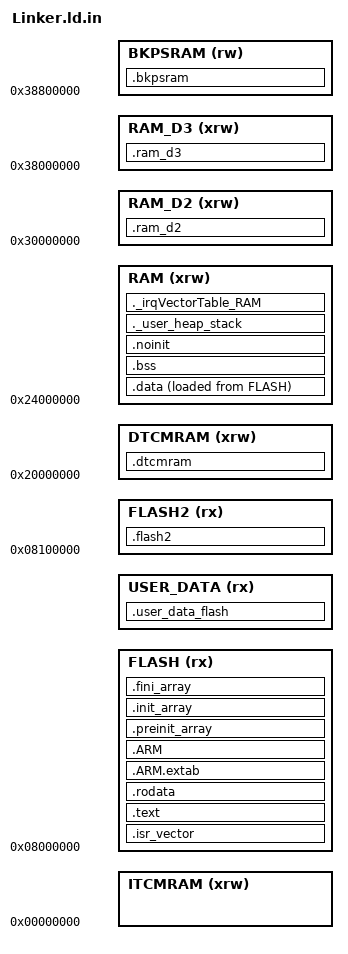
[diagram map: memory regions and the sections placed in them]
/*******************************************************************************
**
** @file        : Linker.ld.in
**
** @author      : Eifell
**
** @brief       : Linker script for STM32H7xx Device from STM32H7 series
**
**                Set heap size, stack size and stack location according
**                to application requirements.
**
**                Set memory bank area and size if external memory is used
**
**  Target      : STMicroelectronics STM32H7 family
**
**  Distribution: The file is distributed as is, without any warranty
**                of any kind.
**
********************************************************************************
** @attention
**
** This software is licensed under terms that can be found in the LICENSE file
** in the root directory of this software component.
** If no LICENSE file comes with this software, it is provided AS-IS.
**
********************************************************************************
*/

/* Entry Point */
ENTRY(StartUp_Handler)

/* Memories definition
 * RAM is the AXI SRAM (D1 / CD domain) - accessible by the CPU and by all DMA
 * controllers. DTCMRAM / ITCMRAM are accessible by the CPU (and MDMA) only.
 * RAM_D2 is the AHB SRAM of D2 / CD domain, RAM_D3 the SRAM of D3 / SRD domain
 * (the only RAM accessible by BDMA). FLASH is bank 1, FLASH2 is bank 2 when the
 * banks are not contiguous (1M dual-bank devices), dual-core devices use bank 1
 * only. */
MEMORY
{
  RAM      (xrw) : ORIGIN = 0x24000000,                    LENGTH = @RAM_SIZE@
  DTCMRAM  (xrw) : ORIGIN = 0x20000000,                    LENGTH = @DTCMRAM_SIZE@
  ITCMRAM  (xrw) : ORIGIN = 0x00000000,                    LENGTH = @ITCMRAM_SIZE@
  RAM_D2   (xrw) : ORIGIN = 0x30000000,                    LENGTH = @RAM_D2_SIZE@
  RAM_D3   (xrw) : ORIGIN = 0x38000000,                    LENGTH = @RAM_D3_SIZE@
  BKPSRAM   (rw) : ORIGIN = 0x38800000,                    LENGTH = @BKPSRAM_SIZE@
  FLASH     (rx) : ORIGIN = 0x08000000,                    LENGTH = @FLASH_SIZE@ - @USER_DATA_SIZE@
  USER_DATA (rx) : ORIGIN = ORIGIN(FLASH) + LENGTH(FLASH), LENGTH = @USER_DATA_SIZE@
  FLASH2    (rx) : ORIGIN = 0x08100000,                    LENGTH = @FLASH2_SIZE@
}

_ram_start  = ORIGIN(RAM);
_ram_length = LENGTH(RAM);
_ram_end    = ORIGIN(RAM) + LENGTH(RAM);

_dtcmram_start  = ORIGIN(DTCMRAM);
_dtcmram_length = LENGTH(DTCMRAM);
_dtcmram_end    = ORIGIN(DTCMRAM) + LENGTH(DTCMRAM);

_itcmram_start  = ORIGIN(ITCMRAM);
_itcmram_length = LENGTH(ITCMRAM);
_itcmram_end    = ORIGIN(ITCMRAM) + LENGTH(ITCMRAM);

_ram_d2_start  = ORIGIN(RAM_D2);
_ram_d2_length = LENGTH(RAM_D2);
_ram_d2_end    = ORIGIN(RAM_D2) + LENGTH(RAM_D2);

_ram_d3_start  = ORIGIN(RAM_D3);
_ram_d3_length = LENGTH(RAM_D3);
_ram_d3_end    = ORIGIN(RAM_D3) + LENGTH(RAM_D3);

_bkpsram_start  = ORIGIN(BKPSRAM);
_bkpsram_length = LENGTH(BKPSRAM);
_bkpsram_end    = ORIGIN(BKPSRAM) + LENGTH(BKPSRAM);

_flash_start  = ORIGIN(FLASH);
_flash_length = LENGTH(FLASH);
_flash_end    = ORIGIN(FLASH) + LENGTH(FLASH);

_flash2_start  = ORIGIN(FLASH2);
_flash2_length = LENGTH(FLASH2);
_flash2_end    = ORIGIN(FLASH2) + LENGTH(FLASH2);


/* Highest address of the user mode stack */
_estack = ORIGIN(RAM) + LENGTH(RAM); /* end of "RAM" Ram type memory */

_Min_Heap_Size = 0x200;  /* required amount of heap */
_Min_Stack_Size = 0x400; /* required amount of stack */


/* Sections */
SECTIONS
{
  /* The startup code into "FLASH" Rom type memory */
  .isr_vector (READONLY) :
  {
    . = ALIGN(4);
    KEEP(*(.isr_vector)) /* Startup code */
    . = ALIGN(4);
  } >FLASH


  /* The program code and other data into "FLASH" Rom type memory */
  .text :
  {
    . = ALIGN(4);
    *(.text)           /* .text sections (code) */
    *(.text*)          /* .text* sections (code) */
    *(.glue_7)         /* glue arm to thumb code */
    *(.glue_7t)        /* glue thumb to arm code */
    *(.eh_frame)

    KEEP (*(.init))
    KEEP (*(.fini))

    . = ALIGN(4);
    _etext = .;        /* define a global symbols at end of code */
  } >FLASH


  /* Constant data into "FLASH" Rom type memory */
  .rodata :
  {
    . = ALIGN(4);
    *(.rodata)         /* .rodata sections (constants, strings, etc.) */
    *(.rodata*)        /* .rodata* sections (constants, strings, etc.) */
    . = ALIGN(4);
  } >FLASH


  /* Location of user data */
  .user_data_flash ( NOLOAD ):
  {
    . = ALIGN(4);
    _user_data_flash_start = .;
    *(.user_data_flash)
    _user_data_flash_end = .;
    . = ALIGN(4);
  } >USER_DATA


  .ARM.extab :
  {
    . = ALIGN(4);
    *(.ARM.extab* .gnu.linkonce.armextab.*)
    . = ALIGN(4);
  } >FLASH


  .ARM :
  {
    . = ALIGN(4);
    __exidx_start = .;
    *(.ARM.exidx*)
    __exidx_end = .;
    . = ALIGN(4);
  } >FLASH


  .preinit_array (READONLY) :
  {
    . = ALIGN(4);
    PROVIDE_HIDDEN (__preinit_array_start = .);
    KEEP (*(.preinit_array*))
    PROVIDE_HIDDEN (__preinit_array_end = .);
    . = ALIGN(4);
  } >FLASH


  .init_array (READONLY) :
  {
    . = ALIGN(4);
    PROVIDE_HIDDEN (__init_array_start = .);
    KEEP (*(SORT(.init_array.*)))
    KEEP (*(.init_array*))
    PROVIDE_HIDDEN (__init_array_end = .);
    . = ALIGN(4);
  } >FLASH


  .fini_array (READONLY) :
  {
    . = ALIGN(4);
    PROVIDE_HIDDEN (__fini_array_start = .);
    KEEP (*(SORT(.fini_array.*)))
    KEEP (*(.fini_array*))
    PROVIDE_HIDDEN (__fini_array_end = .);
    . = ALIGN(4);
  } >FLASH


  /* Used by the startup to initialize data */
  _sidata = LOADADDR(.data);

  /* Initialized data sections into "RAM" Ram type memory */
  .data :
  {
    . = ALIGN(4);
    _sdata = .;        /* create a global symbol at data start */
    *(.data)           /* .data sections */
    *(.data*)          /* .data* sections */
    *(.RamFunc)        /* .RamFunc sections */
    *(.RamFunc*)       /* .RamFunc* sections */

    . = ALIGN(4);
    _edata = .;        /* define a global symbol at data end */

  } >RAM AT> FLASH


  /* Uninitialized data section into "RAM" Ram type memory */
  . = ALIGN(4);
  .bss :
  {
    /* This is used by the startup in order to initialize the .bss section */
    _sbss = .;         /* define a global symbol at bss start */
    __bss_start__ = _sbss;
    *(.bss)
    *(.bss*)
    *(COMMON)

    . = ALIGN(4);
    _ebss = .;         /* define a global symbol at bss end */
    __bss_end__ = _ebss;
  } >RAM


  /* Data not initialized by StartUp - content is kept over system reset
   * (eg. result mailbox of integration test firmware) */
  .noinit (NOLOAD) :
  {
    . = ALIGN(4);
    *(.noinit)
    *(.noinit*)
    . = ALIGN(4);
  } >RAM


  /* User_heap_stack section, used to check that there is enough "RAM" Ram  type memory left */
  ._user_heap_stack :
  {
    . = ALIGN(8);
    PROVIDE ( end = . );
    PROVIDE ( _end = . );
    . = . + _Min_Heap_Size;
    . = . + _Min_Stack_Size;
    . = ALIGN(8);
  } >RAM


    /* Application interrupt vector table located in RAM. Content is written
     * at runtime by NVIC module (Nvic_Init), nothing is loaded from FLASH. */
  ._irqVectorTable_RAM (NOLOAD) :
  {
      /* VTOR requires alignment to power of two >= (count of exceptions x 4),
       * STM32H7 table has up to 716 bytes (STM32H723/H725/H730/H733/H735) */
      . = ALIGN(1024);
      _irqVectorTable_RAM_Start = .;

      KEEP( *(._irqVectorTable_RAM))
      KEEP( *(._irqVectorTable_RAM*))

      _irqVectorTable_RAM_End = .;
  } >RAM


  /* Data placed into DTCM (128K, 64K on STM32H7R/S) - zero wait state RAM of
   * the CPU, not accessible by DMA1 / DMA2 / BDMA. Content is not initialized
   * by StartUp. */
  .dtcmram (NOLOAD) :
  {
    . = ALIGN(4);
    _sdtcmram = .;
    *(.dtcmram)
    *(.dtcmram*)
    . = ALIGN(4);
    _edtcmram = .;
  } >DTCMRAM


  /* Data placed into the AHB SRAM of D2 / CD domain (DMA1 / DMA2 buffers of
   * D2 peripherals, Ethernet descriptors, ...). Content is not initialized by
   * StartUp. */
  .ram_d2 (NOLOAD) :
  {
    . = ALIGN(4);
    _sram_d2 = .;
    *(.ram_d2)
    *(.ram_d2*)
    . = ALIGN(4);
    _eram_d2 = .;
  } >RAM_D2


  /* Data placed into the SRAM of D3 / SRD domain - the only RAM accessible by
   * BDMA (not available on STM32H7R/S). Content is not initialized by StartUp. */
  .ram_d3 (NOLOAD) :
  {
    . = ALIGN(4);
    _sram_d3 = .;
    *(.ram_d3)
    *(.ram_d3*)
    . = ALIGN(4);
    _eram_d3 = .;
  } >RAM_D3


  /* Data placed into Backup SRAM (4K, battery backed when VBAT is supplied).
   * BKPSRAM clock and backup domain write access have to be enabled before
   * use. Content is not initialized by StartUp. */
  .bkpsram (NOLOAD) :
  {
    . = ALIGN(4);
    _sbkpsram = .;
    *(.bkpsram)
    *(.bkpsram*)
    . = ALIGN(4);
    _ebkpsram = .;
  } >BKPSRAM


  /* Constant data placed into FLASH bank 2 of 1M dual-bank devices (bank 2 is
   * not contiguous with bank 1) */
  .flash2 (READONLY) :
  {
    . = ALIGN(4);
    _sflash2 = .;
    KEEP(*(.flash2))
    KEEP(*(.flash2*))
    . = ALIGN(4);
    _eflash2 = .;
  } >FLASH2


  /* Remove information from the compiler libraries */
  /DISCARD/ :
  {
    libc.a ( * )
    libm.a ( * )
    libgcc.a ( * )
  }

  .ARM.attributes 0 : { *(.ARM.attributes) }
}
